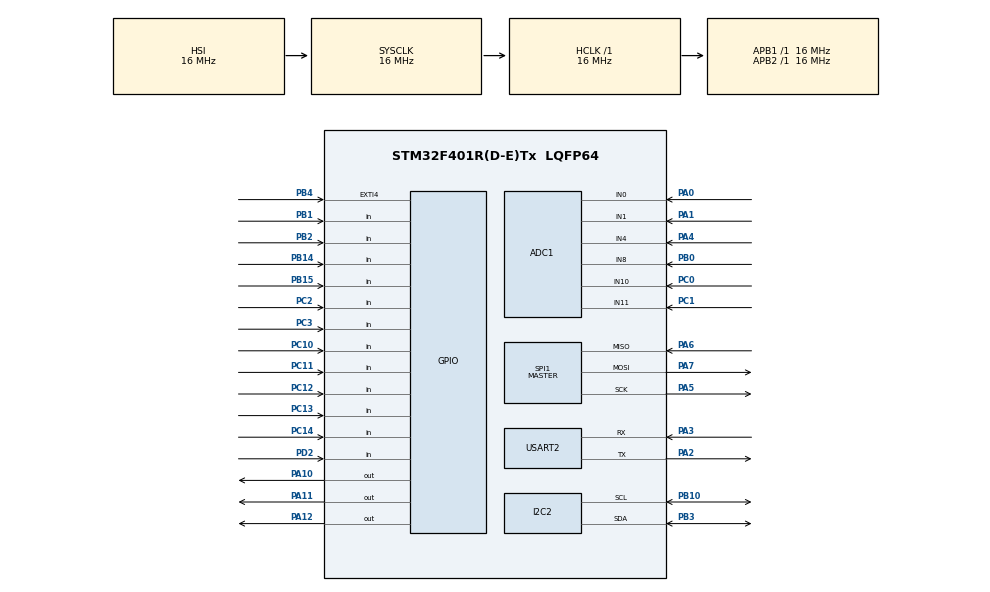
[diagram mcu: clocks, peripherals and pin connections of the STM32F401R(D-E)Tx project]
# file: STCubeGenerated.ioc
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ADC1.Channel-0\#ChannelRegularConversion=ADC_CHANNEL_0
ADC1.Channel-1\#ChannelRegularConversion=ADC_CHANNEL_1
ADC1.Channel-2\#ChannelRegularConversion=ADC_CHANNEL_4
ADC1.Channel-3\#ChannelRegularConversion=ADC_CHANNEL_8
ADC1.Channel-4\#ChannelRegularConversion=ADC_CHANNEL_10
ADC1.Channel-5\#ChannelRegularConversion=ADC_CHANNEL_11
ADC1.ClockPrescaler=ADC_CLOCK_SYNC_PCLK_DIV4
ADC1.ContinuousConvMode=ENABLE
ADC1.DMAContinuousRequests=ENABLE
ADC1.EOCSelection=ADC_EOC_SEQ_CONV
ADC1.InjNumberOfConversion=0
ADC1.NbrOfConversion=6
ADC1.NbrOfConversionFlag=1
ADC1.Rank-0\#ChannelRegularConversion=1
ADC1.Rank-1\#ChannelRegularConversion=2
ADC1.Rank-2\#ChannelRegularConversion=3
ADC1.Rank-3\#ChannelRegularConversion=4
ADC1.Rank-4\#ChannelRegularConversion=5
ADC1.Rank-5\#ChannelRegularConversion=6
ADC1.SamplingTime-0\#ChannelRegularConversion=ADC_SAMPLETIME_3CYCLES
ADC1.SamplingTime-1\#ChannelRegularConversion=ADC_SAMPLETIME_3CYCLES
ADC1.SamplingTime-2\#ChannelRegularConversion=ADC_SAMPLETIME_3CYCLES
ADC1.SamplingTime-3\#ChannelRegularConversion=ADC_SAMPLETIME_3CYCLES
ADC1.SamplingTime-4\#ChannelRegularConversion=ADC_SAMPLETIME_3CYCLES
ADC1.SamplingTime-5\#ChannelRegularConversion=ADC_SAMPLETIME_3CYCLES
ADC1.ScanConvMode=ENABLE
ADC1.master=1
Dma.ADC1.0.Direction=DMA_PERIPH_TO_MEMORY
Dma.ADC1.0.FIFOMode=DMA_FIFOMODE_DISABLE
Dma.ADC1.0.Instance=DMA2_Stream0
Dma.ADC1.0.MemDataAlignment=DMA_MDATAALIGN_WORD
Dma.ADC1.0.MemInc=DMA_MINC_ENABLE
Dma.ADC1.0.Mode=DMA_CIRCULAR
Dma.ADC1.0.PeriphDataAlignment=DMA_PDATAALIGN_WORD
Dma.ADC1.0.PeriphInc=DMA_PINC_DISABLE
Dma.ADC1.0.Priority=DMA_PRIORITY_LOW
Dma.Request0=ADC1
Mcu.Family=STM32F4
Mcu.Name=STM32F401R(D-E)Tx
Mcu.Package=LQFP64
NVIC.DMA2_Stream0_IRQn=true\:0\:0\:false\:false\:true\:false
NVIC.EXTI4_IRQn=true\:1\:0\:true\:false\:true\:true
NVIC.PriorityGroup=NVIC_PRIORITYGROUP_4
NVIC.SPI1_IRQn=true\:1\:0\:true\:false\:true\:true
NVIC.USART2_IRQn=true\:1\:0\:true\:false\:true\:true
PA0-WKUP.Signal=ADCx_IN0
PA1.Signal=ADCx_IN1
PA10.Signal=GPIO_Output
PA11.Signal=GPIO_Output
PA12.Signal=GPIO_Output
PA2.Mode=Asynchronous
PA2.Signal=USART2_TX
PA3.Mode=Asynchronous
PA3.Signal=USART2_RX
PA4.Signal=ADCx_IN4
PA5.Mode=Full_Duplex_Master
PA5.Signal=SPI1_SCK
PA6.Mode=Full_Duplex_Master
PA6.Signal=SPI1_MISO
PA7.Mode=Full_Duplex_Master
PA7.Signal=SPI1_MOSI
PB0.Signal=ADCx_IN8
PB1.Signal=GPIO_Input
PB10.Mode=I2C
PB10.Signal=I2C2_SCL
PB14.Signal=GPIO_Input
PB15.Signal=GPIO_Input
PB2.Signal=GPIO_Input
PB3.Mode=I2C
PB3.Signal=I2C2_SDA
PB4.Signal=GPXTI4
PB6.Signal=S_TIM4_CH1
PB7.Signal=S_TIM4_CH2
PB8.Signal=S_TIM4_CH3
PC0.Signal=ADCx_IN10
PC1.Signal=ADCx_IN11
PC10.Signal=GPIO_Input
PC11.Signal=GPIO_Input
PC12.Signal=GPIO_Input
PC13-ANTI_TAMP.Signal=GPIO_Input
PC14-OSC32_IN.Signal=GPIO_Input
PC2.Signal=GPIO_Input
PC3.Signal=GPIO_Input
PD2.Signal=GPIO_Input
ProjectManager.HeapSize=0x200
ProjectManager.StackSize=0x400
ProjectManager.TargetToolchain=MDK-ARM V5
RCC.AHBFreq_Value=16000000
RCC.APB1Freq_Value=16000000
RCC.APB2Freq_Value=16000000
RCC.CortexFreq_Value=16000000
RCC.HSE_VALUE=25000000
RCC.HSI_VALUE=16000000
RCC.LSE_VALUE=32768
RCC.SYSCLKFreq_VALUE=16000000
RCC.VCOOutputFreq_Value=192000000
SH.ADCx_IN0.0=ADC1_IN0,IN0
SH.ADCx_IN1.0=ADC1_IN1,IN1
SH.ADCx_IN10.0=ADC1_IN10,IN10
SH.ADCx_IN11.0=ADC1_IN11,IN11
SH.ADCx_IN4.0=ADC1_IN4,IN4
SH.ADCx_IN8.0=ADC1_IN8,IN8
SH.S_TIM4_CH1.0=TIM4_CH1
SH.S_TIM4_CH2.0=TIM4_CH2
SH.S_TIM4_CH3.0=TIM4_CH3
SPI1.Direction=SPI_DIRECTION_2LINES
SPI1.Mode=SPI_MODE_MASTER
SPI1.VirtualType=VM_MASTER
USART2.VirtualMode=VM_ASYNC
board=STCubeGenerated

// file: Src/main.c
/**
  ******************************************************************************
  * File Name          : main.c
  * Description        : Main program body
  ******************************************************************************
  ** This notice applies to any and all portions of this file
  * that are not between comment pairs USER CODE BEGIN and
  * USER CODE END. Other portions of this file, whether
  * inserted by the user or by software development tools
  * are owned by their respective copyright owners.
  *
  * COPYRIGHT(c) 2018 STMicroelectronics
  *
  * Redistribution and use in source and binary forms, with or without modification,
  * are permitted provided that the following conditions are met:
  *   1. Redistributions of source code must retain the above copyright notice,
  *      this list of conditions and the following disclaimer.
  *   2. Redistributions in binary form must reproduce the above copyright notice,
  *      this list of conditions and the following disclaimer in the documentation
  *      and/or other materials provided with the distribution.
  *   3. Neither the name of STMicroelectronics nor the names of its contributors
  *      may be used to endorse or promote products derived from this software
  *      without specific prior written permission.
  *
  * THIS SOFTWARE IS PROVIDED BY THE COPYRIGHT HOLDERS AND CONTRIBUTORS "AS IS"
  * AND ANY EXPRESS OR IMPLIED WARRANTIES, INCLUDING, BUT NOT LIMITED TO, THE
  * IMPLIED WARRANTIES OF MERCHANTABILITY AND FITNESS FOR A PARTICULAR PURPOSE ARE
  * DISCLAIMED. IN NO EVENT SHALL THE COPYRIGHT HOLDER OR CONTRIBUTORS BE LIABLE
  * FOR ANY DIRECT, INDIRECT, INCIDENTAL, SPECIAL, EXEMPLARY, OR CONSEQUENTIAL
  * DAMAGES (INCLUDING, BUT NOT LIMITED TO, PROCUREMENT OF SUBSTITUTE GOODS OR
  * SERVICES; LOSS OF USE, DATA, OR PROFITS; OR BUSINESS INTERRUPTION) HOWEVER
  * CAUSED AND ON ANY THEORY OF LIABILITY, WHETHER IN CONTRACT, STRICT LIABILITY,
  * OR TORT (INCLUDING NEGLIGENCE OR OTHERWISE) ARISING IN ANY WAY OUT OF THE USE
  * OF THIS SOFTWARE, EVEN IF ADVISED OF THE POSSIBILITY OF SUCH DAMAGE.
  *
  ******************************************************************************
  */
#include "main.h"
#include "stm32f4xx_hal.h"

/* USER CODE BEGIN Includes */
#define osObjectsPublic                     // define objects in main module
#include "osObjects.h"                      // RTOS object definitions
/* USER CODE END Includes */

ADC_HandleTypeDef hadc1;
DMA_HandleTypeDef hdma_adc1;

I2C_HandleTypeDef hi2c2;

SPI_HandleTypeDef hspi1;

UART_HandleTypeDef huart2;

/* USER CODE BEGIN PV */
/* Private variables ---------------------------------------------------------*/

/* USER CODE END PV */

void SystemClock_Config(void);
static void MX_GPIO_Init(void);
static void MX_DMA_Init(void);
static void MX_I2C2_Init(void);
static void MX_USART2_UART_Init(void);
static void MX_ADC1_Init(void);
static void MX_SPI1_Init(void);

/* USER CODE BEGIN PFP */
/* Private function prototypes -----------------------------------------------*/

/* USER CODE END PFP */

/* USER CODE BEGIN 0 */
extern uint32_t os_time;
uint32_t HAL_GetTick(void) {           // Add HAL_GetTick function for STM32Cube HAL
  return os_time;
}
/* USER CODE END 0 */

int main(void)
{

  /* MCU Configuration----------------------------------------------------------*/

  /* Reset of all peripherals, Initializes the Flash interface and the Systick. */
  HAL_Init();

  /* USER CODE BEGIN Init */
	osKernelInitialize ();
  /* USER CODE END Init */

  /* Configure the system clock */
  SystemClock_Config();

  /* Initialize all configured peripherals */
  MX_GPIO_Init();
  MX_DMA_Init();
  MX_I2C2_Init();
  MX_USART2_UART_Init();
  MX_ADC1_Init();
  MX_SPI1_Init();

  /* USER CODE BEGIN 2 */
		/** Tasks:
		*				- Driving Motors
		*				- Encoders
		*				- IMU
		*				- ADC {HallEffect, TempSensors, VoltSense} (DMA - Background)
		*				- Odroid Comms (UART - BACKGROUND)
		*				- Nucleo Comms (SPI - BACKGROUND)
		*				- Data decode and transmit
		**/

	//Init Threads

	//Activate Background Peripherals

	//Begin Thread Switching
	osKernelStart ();
  /* USER CODE END 2 */

  /* Infinite loop */
  while (1)
  {

  }

}

/** System Clock Configuration
*/
void SystemClock_Config(void)
{

  RCC_OscInitTypeDef RCC_OscInitStruct;
  RCC_ClkInitTypeDef RCC_ClkInitStruct;

    /**Configure the main internal regulator output voltage
    */
  __HAL_RCC_PWR_CLK_ENABLE();

  __HAL_PWR_VOLTAGESCALING_CONFIG(PWR_REGULATOR_VOLTAGE_SCALE2);

    /**Initializes the CPU, AHB and APB busses clocks
    */
  RCC_OscInitStruct.OscillatorType = RCC_OSCILLATORTYPE_HSI;
  RCC_OscInitStruct.HSIState = RCC_HSI_ON;
  RCC_OscInitStruct.HSICalibrationValue = 16;
  RCC_OscInitStruct.PLL.PLLState = RCC_PLL_NONE;
  if (HAL_RCC_OscConfig(&RCC_OscInitStruct) != HAL_OK)
  {
    _Error_Handler(__FILE__, __LINE__);
  }

    /**Initializes the CPU, AHB and APB busses clocks
    */
  RCC_ClkInitStruct.ClockType = RCC_CLOCKTYPE_HCLK|RCC_CLOCKTYPE_SYSCLK
                              |RCC_CLOCKTYPE_PCLK1|RCC_CLOCKTYPE_PCLK2;
  RCC_ClkInitStruct.SYSCLKSource = RCC_SYSCLKSOURCE_HSI;
  RCC_ClkInitStruct.AHBCLKDivider = RCC_SYSCLK_DIV1;
  RCC_ClkInitStruct.APB1CLKDivider = RCC_HCLK_DIV1;
  RCC_ClkInitStruct.APB2CLKDivider = RCC_HCLK_DIV1;

  if (HAL_RCC_ClockConfig(&RCC_ClkInitStruct, FLASH_LATENCY_0) != HAL_OK)
  {
    _Error_Handler(__FILE__, __LINE__);
  }

    /**Configure the Systick interrupt time
    */
  HAL_SYSTICK_Config(HAL_RCC_GetHCLKFreq()/1000);

    /**Configure the Systick
    */
  HAL_SYSTICK_CLKSourceConfig(SYSTICK_CLKSOURCE_HCLK);

  /* SysTick_IRQn interrupt configuration */
  HAL_NVIC_SetPriority(SysTick_IRQn, 15, 0);
}

/* ADC1 init function */
static void MX_ADC1_Init(void)
{

  ADC_ChannelConfTypeDef sConfig;

    /**Configure the global features of the ADC (Clock, Resolution, Data Alignment and number of conversion)
    */
  hadc1.Instance = ADC1;
  hadc1.Init.ClockPrescaler = ADC_CLOCK_SYNC_PCLK_DIV4;
  hadc1.Init.Resolution = ADC_RESOLUTION_12B;
  hadc1.Init.ScanConvMode = ENABLE;
  hadc1.Init.ContinuousConvMode = ENABLE;
  hadc1.Init.DiscontinuousConvMode = DISABLE;
  hadc1.Init.ExternalTrigConvEdge = ADC_EXTERNALTRIGCONVEDGE_NONE;
  hadc1.Init.ExternalTrigConv = ADC_SOFTWARE_START;
  hadc1.Init.DataAlign = ADC_DATAALIGN_RIGHT;
  hadc1.Init.NbrOfConversion = 6;
  hadc1.Init.DMAContinuousRequests = ENABLE;
  hadc1.Init.EOCSelection = ADC_EOC_SEQ_CONV;
  if (HAL_ADC_Init(&hadc1) != HAL_OK)
  {
    _Error_Handler(__FILE__, __LINE__);
  }

    /**Configure for the selected ADC regular channel its corresponding rank in the sequencer and its sample time.
    */
  sConfig.Channel = ADC_CHANNEL_0;
  sConfig.Rank = 1;
  sConfig.SamplingTime = ADC_SAMPLETIME_3CYCLES;
  if (HAL_ADC_ConfigChannel(&hadc1, &sConfig) != HAL_OK)
  {
    _Error_Handler(__FILE__, __LINE__);
  }

    /**Configure for the selected ADC regular channel its corresponding rank in the sequencer and its sample time.
    */
  sConfig.Channel = ADC_CHANNEL_1;
  sConfig.Rank = 2;
  if (HAL_ADC_ConfigChannel(&hadc1, &sConfig) != HAL_OK)
  {
    _Error_Handler(__FILE__, __LINE__);
  }

    /**Configure for the selected ADC regular channel its corresponding rank in the sequencer and its sample time.
    */
  sConfig.Channel = ADC_CHANNEL_4;
  sConfig.Rank = 3;
  if (HAL_ADC_ConfigChannel(&hadc1, &sConfig) != HAL_OK)
  {
    _Error_Handler(__FILE__, __LINE__);
  }

    /**Configure for the selected ADC regular channel its corresponding rank in the sequencer and its sample time.
    */
  sConfig.Channel = ADC_CHANNEL_8;
  sConfig.Rank = 4;
  if (HAL_ADC_ConfigChannel(&hadc1, &sConfig) != HAL_OK)
  {
    _Error_Handler(__FILE__, __LINE__);
  }

    /**Configure for the selected ADC regular channel its corresponding rank in the sequencer and its sample time.
    */
  sConfig.Channel = ADC_CHANNEL_10;
  sConfig.Rank = 5;
  if (HAL_ADC_ConfigChannel(&hadc1, &sConfig) != HAL_OK)
  {
    _Error_Handler(__FILE__, __LINE__);
  }

    /**Configure for the selected ADC regular channel its corresponding rank in the sequencer and its sample time.
    */
  sConfig.Channel = ADC_CHANNEL_11;
  sConfig.Rank = 6;
  if (HAL_ADC_ConfigChannel(&hadc1, &sConfig) != HAL_OK)
  {
    _Error_Handler(__FILE__, __LINE__);
  }

}

/* I2C2 init function */
static void MX_I2C2_Init(void)
{

  hi2c2.Instance = I2C2;
  hi2c2.Init.ClockSpeed = 100000;
  hi2c2.Init.DutyCycle = I2C_DUTYCYCLE_2;
  hi2c2.Init.OwnAddress1 = 0;
  hi2c2.Init.AddressingMode = I2C_ADDRESSINGMODE_7BIT;
  hi2c2.Init.DualAddressMode = I2C_DUALADDRESS_DISABLE;
  hi2c2.Init.OwnAddress2 = 0;
  hi2c2.Init.GeneralCallMode = I2C_GENERALCALL_DISABLE;
  hi2c2.Init.NoStretchMode = I2C_NOSTRETCH_DISABLE;
  if (HAL_I2C_Init(&hi2c2) != HAL_OK)
  {
    _Error_Handler(__FILE__, __LINE__);
  }

}

/* SPI1 init function */
static void MX_SPI1_Init(void)
{

  /* SPI1 parameter configuration*/
  hspi1.Instance = SPI1;
  hspi1.Init.Mode = SPI_MODE_MASTER;
  hspi1.Init.Direction = SPI_DIRECTION_2LINES;
  hspi1.Init.DataSize = SPI_DATASIZE_8BIT;
  hspi1.Init.CLKPolarity = SPI_POLARITY_LOW;
  hspi1.Init.CLKPhase = SPI_PHASE_1EDGE;
  hspi1.Init.NSS = SPI_NSS_SOFT;
  hspi1.Init.BaudRatePrescaler = SPI_BAUDRATEPRESCALER_2;
  hspi1.Init.FirstBit = SPI_FIRSTBIT_MSB;
  hspi1.Init.TIMode = SPI_TIMODE_DISABLE;
  hspi1.Init.CRCCalculation = SPI_CRCCALCULATION_DISABLE;
  hspi1.Init.CRCPolynomial = 10;
  if (HAL_SPI_Init(&hspi1) != HAL_OK)
  {
    _Error_Handler(__FILE__, __LINE__);
  }

}

/* USART2 init function */
static void MX_USART2_UART_Init(void)
{

  huart2.Instance = USART2;
  huart2.Init.BaudRate = 115200;
  huart2.Init.WordLength = UART_WORDLENGTH_8B;
  huart2.Init.StopBits = UART_STOPBITS_1;
  huart2.Init.Parity = UART_PARITY_NONE;
  huart2.Init.Mode = UART_MODE_TX_RX;
  huart2.Init.HwFlowCtl = UART_HWCONTROL_NONE;
  huart2.Init.OverSampling = UART_OVERSAMPLING_16;
  if (HAL_UART_Init(&huart2) != HAL_OK)
  {
    _Error_Handler(__FILE__, __LINE__);
  }

}

static void MX_DMA_Init(void)
{
  /* DMA controller clock enable */
  __HAL_RCC_DMA2_CLK_ENABLE();

  /* DMA interrupt init */
  /* DMA2_Stream0_IRQn interrupt configuration */
  HAL_NVIC_SetPriority(DMA2_Stream0_IRQn, 0, 0);
  HAL_NVIC_EnableIRQ(DMA2_Stream0_IRQn);

}

/** Configure pins as
        * Analog
        * Input
        * Output
        * EVENT_OUT
        * EXTI
     PB6   ------> S_TIM4_CH1
     PB7   ------> S_TIM4_CH2
     PB8   ------> S_TIM4_CH3
*/
static void MX_GPIO_Init(void)
{

  GPIO_InitTypeDef GPIO_InitStruct;

  /* GPIO Ports Clock Enable */
  __HAL_RCC_GPIOC_CLK_ENABLE();
  __HAL_RCC_GPIOA_CLK_ENABLE();
  __HAL_RCC_GPIOB_CLK_ENABLE();
  __HAL_RCC_GPIOD_CLK_ENABLE();

  /*Configure GPIO pin Output Level */
  HAL_GPIO_WritePin(GPIOA, GPIO_PIN_10|GPIO_PIN_11|GPIO_PIN_12, GPIO_PIN_RESET);

  /*Configure GPIO pins : PC13 PC14 PC2 PC3
                           PC10 PC11 PC12 */
  GPIO_InitStruct.Pin = GPIO_PIN_13|GPIO_PIN_14|GPIO_PIN_2|GPIO_PIN_3
                          |GPIO_PIN_10|GPIO_PIN_11|GPIO_PIN_12;
  GPIO_InitStruct.Mode = GPIO_MODE_INPUT;
  GPIO_InitStruct.Pull = GPIO_NOPULL;
  HAL_GPIO_Init(GPIOC, &GPIO_InitStruct);

  /*Configure GPIO pins : PB1 PB2 PB14 PB15 */
  GPIO_InitStruct.Pin = GPIO_PIN_1|GPIO_PIN_2|GPIO_PIN_14|GPIO_PIN_15;
  GPIO_InitStruct.Mode = GPIO_MODE_INPUT;
  GPIO_InitStruct.Pull = GPIO_NOPULL;
  HAL_GPIO_Init(GPIOB, &GPIO_InitStruct);

  /*Configure GPIO pins : PA10 PA11 PA12 */
  GPIO_InitStruct.Pin = GPIO_PIN_10|GPIO_PIN_11|GPIO_PIN_12;
  GPIO_InitStruct.Mode = GPIO_MODE_OUTPUT_PP;
  GPIO_InitStruct.Pull = GPIO_NOPULL;
  GPIO_InitStruct.Speed = GPIO_SPEED_FREQ_LOW;
  HAL_GPIO_Init(GPIOA, &GPIO_InitStruct);

  /*Configure GPIO pin : PD2 */
  GPIO_InitStruct.Pin = GPIO_PIN_2;
  GPIO_InitStruct.Mode = GPIO_MODE_INPUT;
  GPIO_InitStruct.Pull = GPIO_NOPULL;
  HAL_GPIO_Init(GPIOD, &GPIO_InitStruct);

  /*Configure GPIO pin : PB4 */
  GPIO_InitStruct.Pin = GPIO_PIN_4;
  GPIO_InitStruct.Mode = GPIO_MODE_IT_RISING;
  GPIO_InitStruct.Pull = GPIO_NOPULL;
  HAL_GPIO_Init(GPIOB, &GPIO_InitStruct);

  /*Configure GPIO pins : PB6 PB7 PB8 */
  GPIO_InitStruct.Pin = GPIO_PIN_6|GPIO_PIN_7|GPIO_PIN_8;
  GPIO_InitStruct.Mode = GPIO_MODE_AF_PP;
  GPIO_InitStruct.Pull = GPIO_NOPULL;
  GPIO_InitStruct.Speed = GPIO_SPEED_FREQ_LOW;
  GPIO_InitStruct.Alternate = GPIO_AF2_TIM4;
  HAL_GPIO_Init(GPIOB, &GPIO_InitStruct);

  /* EXTI interrupt init*/
  HAL_NVIC_SetPriority(EXTI4_IRQn, 1, 0);
  HAL_NVIC_EnableIRQ(EXTI4_IRQn);

}

void _Error_Handler(char * file, int line)
{
  while(1)
  {
  }
}

/************************ (C) COPYRIGHT STMicroelectronics *****END OF FILE****/
